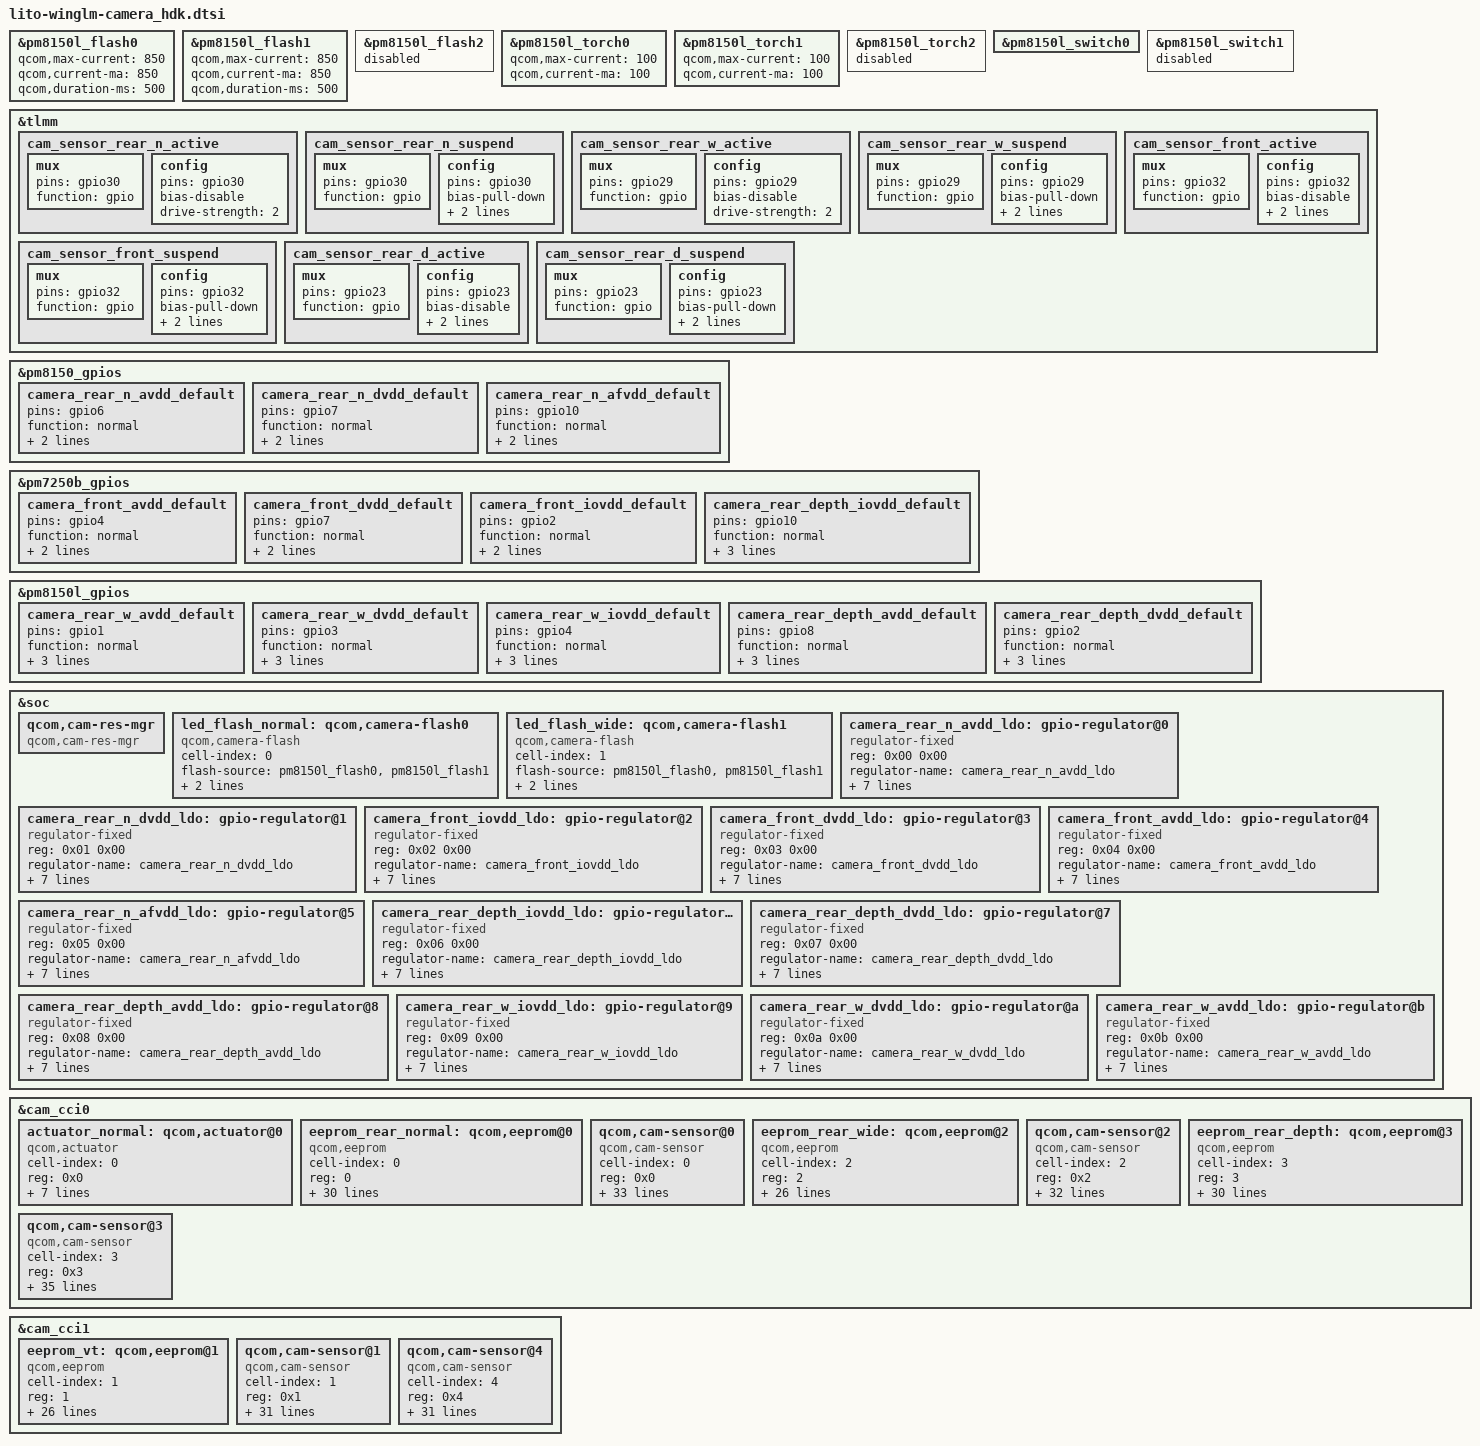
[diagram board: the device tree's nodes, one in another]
#include <dt-bindings/clock/qcom,camcc-lito.h>

&pm8150l_flash0 {
	status = "ok";
	qcom,max-current = <850>;
	qcom,current-ma = <850>;
	qcom,duration-ms = <500>;
};

&pm8150l_flash1 {
	status = "ok";
	qcom,max-current = <850>;
	qcom,current-ma = <850>;
	qcom,duration-ms = <500>;
};

&pm8150l_flash2 {
	status = "disabled";
};

&pm8150l_torch0 {
	status = "ok";
	qcom,max-current = <100>;
	qcom,current-ma = <100>;
};

&pm8150l_torch1 {
	status = "ok";
	qcom,max-current = <100>;
	qcom,current-ma = <100>;
};

&pm8150l_torch2 {
	status = "disabled";
};

&pm8150l_switch0 {
	status = "ok";
};

&pm8150l_switch1 {
	status = "disbled";
};

&tlmm{
	cam_sensor_rear_n_active: cam_sensor_rear_n_active {
		mux {
			pins = "gpio30";
			function = "gpio";
		};

		config {
			pins = "gpio30";
			bias-disable;
			drive-strength = <2>;
		};
	};

	cam_sensor_rear_n_suspend: cam_sensor_rear_n_suspend {
		mux {
			pins = "gpio30";
			function = "gpio";
		};

		config {
			pins = "gpio30";
			bias-pull-down;
			drive-strength = <2>;
			output-low;
		};
	};

	cam_sensor_rear_w_active: cam_sensor_rear_w_active {
		mux {
			pins = "gpio29";
			function = "gpio";
		};

		config {
			pins = "gpio29";
			bias-disable;
			drive-strength = <2>;
		};
	};

	cam_sensor_rear_w_suspend: cam_sensor_rear_w_suspend {
		mux {
			pins = "gpio29";
			function = "gpio";
		};

		config {
			pins = "gpio29";
			bias-pull-down;
			drive-strength = <2>;
			output-low;
		};
	};

	cam_sensor_front_active: cam_sensor_front_active {
		mux {
			pins = "gpio32";
			function = "gpio";
		};

		config {
			pins = "gpio32";
			bias-disable;
			drive-strength = <2>;
			output-low;
		};
	};

	cam_sensor_front_suspend: cam_sensor_front_suspend {
		mux {
			pins = "gpio32";
			function = "gpio";
		};

		config {
			pins = "gpio32";
			bias-pull-down;
			drive-strength = <2>;
			output-low;
		};
	};

	cam_sensor_rear_d_active: cam_sensor_rear_d_active {
		mux {
			pins = "gpio23";
			function = "gpio";
		};

		config {
			pins = "gpio23";
			bias-disable;
			drive-strength = <2>;
			output-low;
		};
	};
	
	cam_sensor_rear_d_suspend: cam_sensor_rear_d_suspend {
		mux {
			pins = "gpio23";
			function = "gpio";
		};

		config {
			pins = "gpio23";
			bias-pull-down;
			drive-strength = <2>;
			output-low;
		};
	};
};

&pm8150_gpios {
	camera_rear_n_avdd_default: camera_rear_n_avdd_default {
		pins = "gpio6";
		function = "normal";
		power-source = <0>;
		output-high;
	};

	camera_rear_n_dvdd_default: camera_rear_n_dvdd_default {
		pins = "gpio7";
		function = "normal";
		power-source = <0>;
		output-high;
	};

	camera_rear_n_afvdd_default: camera_rear_n_afvdd_default {
		pins = "gpio10";
		function = "normal";
		power-source = <0>;
		output-high;
	};
};

&pm7250b_gpios {
	camera_front_avdd_default: camera_front_avdd_default {
		pins = "gpio4";
		function = "normal";
		power-source = <0>;
		output-high;
	};

	camera_front_dvdd_default: camera_front_dvdd_default {
		pins = "gpio7";
		function = "normal";
		power-source = <0>;
		output-high;
	};

	camera_front_iovdd_default: camera_front_iovdd_default {
		pins = "gpio2";
		function = "normal";
		power-source = <0>;
		output-high;
	};

	camera_rear_depth_iovdd_default: camera_rear_depth_iovdd_default {
		pins = "gpio10";
		function = "normal";
		power-source = <0>;
		input-disable;
		output-high;
	};
};

&pm8150l_gpios {
	camera_rear_w_avdd_default: camera_rear_w_avdd_default {
		pins = "gpio1";
		function = "normal";
		power-source = <0>;
		input-disable;
		output-high;
	};

	camera_rear_w_dvdd_default: camera_rear_w_dvdd_default {
		pins = "gpio3";
		function = "normal";
		power-source = <0>;
		input-disable;
		output-high;
	};

	camera_rear_w_iovdd_default: camera_rear_w_iovdd_default {
		pins = "gpio4";
		function = "normal";
		power-source = <0>;
		input-disable;
		output-high;
	};

	camera_rear_depth_avdd_default: camera_rear_depth_avdd_default {
		pins = "gpio8";
		function = "normal";
		power-source = <0>;
		input-disable;
		output-high;
	};
	
	camera_rear_depth_dvdd_default: camera_rear_depth_dvdd_default {
		pins = "gpio2";
		function = "normal";
		power-source = <0>;
		input-disable;
		output-high;
	};
};

&soc {
	qcom,cam-res-mgr {
		compatible = "qcom,cam-res-mgr";
		status = "ok";
	};

	led_flash_normal: qcom,camera-flash0 {
		cell-index = <0>;
		compatible = "qcom,camera-flash";
		flash-source = <&pm8150l_flash0 &pm8150l_flash1>;
		torch-source = <&pm8150l_torch0 &pm8150l_torch1>;
		switch-source = <&pm8150l_switch2>;
		status = "ok";
	};

	led_flash_wide: qcom,camera-flash1 {
		cell-index = <1>;
		compatible = "qcom,camera-flash";
		flash-source = <&pm8150l_flash0 &pm8150l_flash1>;
		torch-source = <&pm8150l_torch0 &pm8150l_torch1>;
		switch-source = <&pm8150l_switch2>;
		status = "ok";
	};

	camera_rear_n_avdd_ldo: gpio-regulator@0 {
		compatible = "regulator-fixed";
		reg = <0x00 0x00>;
		regulator-name = "camera_rear_n_avdd_ldo";
		regulator-min-microvolt = <2800000>;
		regulator-max-microvolt = <2800000>;
		regulator-enable-ramp-delay = <135>;
		enable-active-high;
		gpio = <&pm8150_gpios 6 0>;
		pinctrl-names = "default";
		pinctrl-0 = <&camera_rear_n_avdd_default>;
		vin-supply = <&BOB>;
	};

	camera_rear_n_dvdd_ldo: gpio-regulator@1 {
		compatible = "regulator-fixed";
		reg = <0x01 0x00>;
		regulator-name = "camera_rear_n_dvdd_ldo";
		regulator-min-microvolt = <1050000>;
		regulator-max-microvolt = <1050000>;
		regulator-enable-ramp-delay = <135>;
		enable-active-high;
		gpio = <&pm8150_gpios 7 0>;
		pinctrl-names = "default";
		pinctrl-0 = <&camera_rear_n_dvdd_default>;
		vin-supply = <&S5A>;
	};

	camera_front_iovdd_ldo: gpio-regulator@2 {
		compatible = "regulator-fixed";
		reg = <0x02 0x00>;
		regulator-name = "camera_front_iovdd_ldo";
		regulator-min-microvolt = <1800000>;
		regulator-max-microvolt = <1800000>;
		regulator-enable-ramp-delay = <135>;
		enable-active-high;
		gpio = <&pm7250b_gpios 2 0>;
		pinctrl-names = "default";
		pinctrl-0 = <&camera_front_iovdd_default>;
		vin-supply = <&BOB>;
	};

	camera_front_dvdd_ldo: gpio-regulator@3 {
		compatible = "regulator-fixed";
		reg = <0x03 0x00>;
		regulator-name = "camera_front_dvdd_ldo";
		regulator-min-microvolt = <1050000>;
		regulator-max-microvolt = <1050000>;
		regulator-enable-ramp-delay = <135>;
		enable-active-high;
		gpio = <&pm7250b_gpios 7 0>;
		pinctrl-names = "default";
		pinctrl-0 = <&camera_front_dvdd_default>;
		vin-supply = <&S5A>;
	};

	camera_front_avdd_ldo: gpio-regulator@4 {
		compatible = "regulator-fixed";
		reg = <0x04 0x00>;
		regulator-name = "camera_front_avdd_ldo";
		regulator-min-microvolt = <2800000>;
		regulator-max-microvolt = <2800000>;
		regulator-enable-ramp-delay = <135>;
		enable-active-high;
		gpio = <&pm7250b_gpios 4 0>;
		pinctrl-names = "default";
		pinctrl-0 = <&camera_front_avdd_default>;
		vin-supply = <&BOB>;
	};

	camera_rear_n_afvdd_ldo: gpio-regulator@5 {
		compatible = "regulator-fixed";
		reg = <0x05 0x00>;
		regulator-name = "camera_rear_n_afvdd_ldo";
		regulator-min-microvolt = <2800000>;
		regulator-max-microvolt = <2800000>;
		regulator-enable-ramp-delay = <135>;
		enable-active-high;
		gpio = <&pm8150_gpios 10 0>;
		pinctrl-names = "default";
		pinctrl-0 = <&camera_rear_n_afvdd_default>;
		vin-supply = <&BOB>;
	};

	camera_rear_depth_iovdd_ldo: gpio-regulator@6 {
		compatible = "regulator-fixed";
		reg = <0x06 0x00>;
		regulator-name = "camera_rear_depth_iovdd_ldo";
		regulator-min-microvolt = <1800000>;
		regulator-max-microvolt = <1800000>;
		regulator-enable-ramp-delay = <135>;
		enable-active-high;
		gpio = <&pm7250b_gpios 10 0>;
		pinctrl-names = "default";
		pinctrl-0 = <&camera_rear_depth_iovdd_default>;
		vin-supply = <&BOB>;
	};
	
	camera_rear_depth_dvdd_ldo: gpio-regulator@7 {
		compatible = "regulator-fixed";
		reg = <0x07 0x00>;
		regulator-name = "camera_rear_depth_dvdd_ldo";
		regulator-min-microvolt = <1200000>;
		regulator-max-microvolt = <1200000>;
		regulator-enable-ramp-delay = <135>;
		enable-active-high;
		gpio = <&pm8150l_gpios 2 0>;
		pinctrl-names = "default";
		pinctrl-0 = <&camera_rear_depth_dvdd_default>;
		vin-supply = <&S5A>;
	};

	camera_rear_depth_avdd_ldo: gpio-regulator@8 {
		compatible = "regulator-fixed";
		reg = <0x08 0x00>;
		regulator-name = "camera_rear_depth_avdd_ldo";
		regulator-min-microvolt = <2800000>;
		regulator-max-microvolt = <2800000>;
		regulator-enable-ramp-delay = <135>;
		enable-active-high;
		gpio = <&pm8150l_gpios 8 0>;
		pinctrl-names = "default";
		pinctrl-0 = <&camera_rear_depth_avdd_default>;
		vin-supply = <&BOB>;
	};

	camera_rear_w_iovdd_ldo: gpio-regulator@9 {
		compatible = "regulator-fixed";
		reg = <0x09 0x00>;
		regulator-name = "camera_rear_w_iovdd_ldo";
		regulator-min-microvolt = <1800000>;
		regulator-max-microvolt = <1800000>;
		regulator-enable-ramp-delay = <135>;
		enable-active-high;
		gpio = <&pm8150l_gpios 4 0>;
		pinctrl-names = "default";
		pinctrl-0 = <&camera_rear_w_iovdd_default>;
		vin-supply = <&BOB>;
	};

	camera_rear_w_dvdd_ldo: gpio-regulator@a {
		compatible = "regulator-fixed";
		reg = <0x0a 0x00>;
		regulator-name = "camera_rear_w_dvdd_ldo";
		regulator-min-microvolt = <1200000>;
		regulator-max-microvolt = <1200000>;
		regulator-enable-ramp-delay = <135>;
		enable-active-high;
		gpio = <&pm8150l_gpios 3 0>;
		pinctrl-names = "default";
		pinctrl-0 = <&camera_rear_w_dvdd_default>;
		vin-supply = <&S5A>;
	};

	camera_rear_w_avdd_ldo: gpio-regulator@b {
		compatible = "regulator-fixed";
		reg = <0x0b 0x00>;
		regulator-name = "camera_rear_w_avdd_ldo";
		regulator-min-microvolt = <2800000>;
		regulator-max-microvolt = <2800000>;
		regulator-enable-ramp-delay = <135>;
		enable-active-high;
		gpio = <&pm8150l_gpios 1 0>;
		pinctrl-names = "default";
		pinctrl-0 = <&camera_rear_w_avdd_default>;
		vin-supply = <&BOB>;
	};
};

&cam_cci0 {
	actuator_normal: qcom,actuator@0 {
		cell-index = <0>;
		reg = <0x0>;
		compatible = "qcom,actuator";
		cci-master = <0>;
		cam_vaf-supply = <&camera_rear_n_afvdd_ldo>;
		regulator-names = "cam_vaf";
		rgltr-cntrl-support;
		rgltr-min-voltage = <2800000>;
		rgltr-max-voltage = <2800000>;
		rgltr-load-current = <100000>;
		status = "ok";
	};

	eeprom_rear_normal: qcom,eeprom@0 {
		cell-index = <0>;
		reg = <0>;
		compatible = "qcom,eeprom";
		cam_vio-supply = <&L17A>;
		cam_vana-supply = <&camera_rear_n_avdd_ldo>;
		cam_vdig-supply = <&camera_rear_n_dvdd_ldo>;
		cam_clk-supply = <&titan_top_gdsc>;
		cam_vaf-supply = <&camera_rear_n_afvdd_ldo>;
		regulator-names = "cam_vio", "cam_vana", "cam_vdig",
			"cam_clk", "cam_vaf";
		rgltr-cntrl-support;
		rgltr-min-voltage = <1800000 2800000 1050000 0 2800000>;
		rgltr-max-voltage = <1800000 2800000 1050000 0 2800000>;
		rgltr-load-current = <150000 150000 300000 0 100000>;
		gpio-no-mux = <0>;
		pinctrl-names = "cam_default", "cam_suspend";
		pinctrl-0 = <&cam_sensor_mclk0_active
				 &cam_sensor_rear_n_active>;
		pinctrl-1 = <&cam_sensor_mclk0_suspend
				 &cam_sensor_rear_n_suspend>;
		gpios = <&tlmm 13 0>,
			<&tlmm 30 0>;
		gpio-reset = <1>;
		gpio-req-tbl-num = <0 1>;
		gpio-req-tbl-flags = <1 0>;
		gpio-req-tbl-label = "CAMIF_MCLK0",
					"CAM_RESET0";
		sensor-position = <0>;
		sensor-mode = <0>;
		cci-master = <0>;
		status = "ok";
		clocks = <&camcc CAM_CC_MCLK0_CLK>;
		clock-names = "cam_clk";
		clock-cntl-level = "turbo";
		clock-rates = <19200000>;
	};

	qcom,cam-sensor@0 {
		cell-index = <0>;
		compatible = "qcom,cam-sensor";
		reg = <0x0>;
		csiphy-sd-index = <0>;
		sensor-position-roll = <90>;
		sensor-position-pitch = <0>;
		sensor-position-yaw = <180>;
		eeprom-src = <&eeprom_rear_normal>;
		actuator-src = <&actuator_normal>;
		led-flash-src = <&led_flash_normal>;
		cam_vio-supply = <&L17A>;
		cam_vana-supply = <&camera_rear_n_avdd_ldo>;
		cam_vdig-supply = <&camera_rear_n_dvdd_ldo>;
		cam_clk-supply = <&titan_top_gdsc>;
		regulator-names = "cam_vio", "cam_vana", "cam_vdig", "cam_clk";
		rgltr-cntrl-support;
		rgltr-min-voltage = <1800000 2800000 1050000 0>;
		rgltr-max-voltage = <1800000 2800000 1050000 0>;
		rgltr-load-current = <150000 150000 300000 0>;
		gpio-no-mux = <0>;
		pinctrl-names = "cam_default", "cam_suspend";
		pinctrl-0 = <&cam_sensor_mclk0_active
				 &cam_sensor_rear_n_active>;
		pinctrl-1 = <&cam_sensor_mclk0_suspend
				 &cam_sensor_rear_n_suspend>;
		gpios = <&tlmm 13 0>,
			<&tlmm 30 0>;
		gpio-reset = <1>;
		gpio-req-tbl-num = <0 1>;
		gpio-req-tbl-flags = <1 0>;
		gpio-req-tbl-label = "CAMIF_MCLK0",
					"CAM_RESET0";
		sensor-mode = <0>;
		cci-device = <0>;
		cci-master = <0>;
		status = "ok";
		clocks = <&camcc CAM_CC_MCLK0_CLK>;
		clock-names = "cam_clk";
		clock-cntl-level = "turbo";
		clock-rates = <19200000>;
	};

	eeprom_rear_wide: qcom,eeprom@2 {
		cell-index = <2>;
		reg = <2>;
		compatible = "qcom,eeprom";
		cam_vio-supply = <&camera_rear_w_iovdd_ldo>;
		cam_vana-supply = <&camera_rear_w_avdd_ldo>;
		cam_vdig-supply = <&camera_rear_w_dvdd_ldo>;
		cam_clk-supply = <&titan_top_gdsc>;
		regulator-names = "cam_vio", "cam_vana", "cam_vdig", "cam_clk";
		rgltr-cntrl-support;
		rgltr-min-voltage = <1800000 2800000 1200000 0>;
		rgltr-max-voltage = <1800000 2800000 1200000 0>;
		rgltr-load-current = <150000 150000 300000 0>;
		gpio-no-mux = <0>;
		pinctrl-names = "cam_default", "cam_suspend";
		pinctrl-0 = <&cam_sensor_mclk1_active
				 &cam_sensor_rear_w_active>;
		pinctrl-1 = <&cam_sensor_mclk1_suspend
				 &cam_sensor_rear_w_suspend>;
		gpios = <&tlmm 14 0>,
			<&tlmm 29 0>;
		gpio-reset = <1>;
		gpio-req-tbl-num = <0 1>;
		gpio-req-tbl-flags = <1 0>;
		gpio-req-tbl-label = "CAMIF_MCLK1",
					"CAM_RESET1";
		sensor-position = <0>;
		sensor-mode = <0>;
		cci-master = <1>;
		status = "ok";
		clocks = <&camcc CAM_CC_MCLK1_CLK>;
		clock-names = "cam_clk";
		clock-cntl-level = "turbo";
		clock-rates = <19200000>;
	};

	qcom,cam-sensor@2 {
		cell-index = <2>;
		compatible = "qcom,cam-sensor";
		reg = <0x2>;
		csiphy-sd-index = <1>;
		sensor-position-roll = <90>;
		sensor-position-pitch = <0>;
		sensor-position-yaw = <180>;
		eeprom-src = <&eeprom_rear_wide>;
		led-flash-src = <&led_flash_wide>;
		cam_vio-supply = <&camera_rear_w_iovdd_ldo>;
		cam_vana-supply = <&camera_rear_w_avdd_ldo>;
		cam_vdig-supply = <&camera_rear_w_dvdd_ldo>;
		cam_clk-supply = <&titan_top_gdsc>;
		regulator-names = "cam_vio", "cam_vana", "cam_vdig", "cam_clk";
		rgltr-cntrl-support;
		rgltr-min-voltage = <1800000 2800000 1200000 0>;
		rgltr-max-voltage = <1800000 2800000 1200000 0>;
		rgltr-load-current = <150000 150000 300000 0>;
		gpio-no-mux = <0>;
		pinctrl-names = "cam_default", "cam_suspend";
		pinctrl-0 = <&cam_sensor_mclk1_active
				 &cam_sensor_rear_w_active>;
		pinctrl-1 = <&cam_sensor_mclk1_suspend
				 &cam_sensor_rear_w_suspend>;
		gpios = <&tlmm 14 0>,
			<&tlmm 29 0>;
		gpio-reset = <1>;
		gpio-req-tbl-num = <0 1>;
		gpio-req-tbl-flags = <1 0>;
		gpio-req-tbl-label = "CAMIF_MCLK1",
					"CAM_RESET1";
		sensor-mode = <0>;
		cci-device = <0>;
		cci-master = <1>;
		status = "ok";
		clocks = <&camcc CAM_CC_MCLK1_CLK>;
		clock-names = "cam_clk";
		clock-cntl-level = "turbo";
		clock-rates = <19200000>;
	};

	eeprom_rear_depth: qcom,eeprom@3 {
		cell-index = <3>;
		reg = <3>;
		compatible = "qcom,eeprom";
		cam_vio-supply = <&camera_rear_depth_iovdd_ldo>;
		cam_vana-supply = <&camera_rear_depth_avdd_ldo>;
		cam_vdig-supply = <&camera_rear_depth_dvdd_ldo>;
		cam_v_custom1-supply = <&camera_rear_w_iovdd_ldo>;
		cam_clk-supply = <&titan_top_gdsc>;
		regulator-names = "cam_vio", "cam_vana", "cam_vdig", "cam_clk", "cam_v_custom1";
		rgltr-cntrl-support;
		rgltr-min-voltage = <1800000 2800000 1200000 0 1800000>;
		rgltr-max-voltage = <1800000 2800000 1200000 0 1800000>;
		rgltr-load-current = <150000 150000 300000 0 150000>;
		gpio-no-mux = <0>;
		pinctrl-names = "cam_default", "cam_suspend";
		pinctrl-0 = <&cam_sensor_mclk3_active
				 &cam_sensor_rear_d_active>;
		pinctrl-1 = <&cam_sensor_mclk3_suspend
				 &cam_sensor_rear_d_suspend>;
		gpios = <&tlmm 16 0>,
			<&tlmm 23 0>;
		gpio-reset = <1>;
		gpio-req-tbl-num = <0 1>;
		gpio-req-tbl-flags = <1 0>;
		gpio-req-tbl-label = "DEPTH_MCLK",
					"DEPTH_RESET";
		sensor-position = <0>;
		sensor-mode = <0>;
		cci-master = <1>;
		status = "ok";
		clocks = <&camcc CAM_CC_MCLK3_CLK>;
		clock-names = "cam_clk";
		clock-cntl-level = "turbo";
		clock-rates = <19200000>;
	};

	qcom,cam-sensor@3 {
		cell-index = <3>;
		compatible = "qcom,cam-sensor";
		reg = <0x3>;
		csiphy-sd-index = <3>;
		sensor-position-roll = <90>;
		sensor-position-pitch = <0>;
		sensor-position-yaw = <180>;
		eeprom-src = <&eeprom_rear_depth>;
		cam_vio-supply = <&camera_rear_depth_iovdd_ldo>;
		cam_vana-supply = <&camera_rear_depth_avdd_ldo>;
		cam_vdig-supply = <&camera_rear_depth_dvdd_ldo>;
		cam_v_custom1-supply = <&camera_rear_w_iovdd_ldo>;
		cam_clk-supply = <&titan_top_gdsc>;
		regulator-names = "cam_vio", "cam_vana", "cam_vdig", "cam_clk", "cam_v_custom1";
		rgltr-cntrl-support;
		rgltr-min-voltage = <1800000 2800000 1200000 0 1800000>;
		rgltr-max-voltage = <1800000 2800000 1200000 0 1800000>;
		rgltr-load-current = <150000 150000 300000 0 150000>;
		gpio-no-mux = <0>;
		pinctrl-names = "cam_default", "cam_suspend";
		pinctrl-0 = <&cam_sensor_mclk3_active
				 &cam_sensor_rear_d_active>;
		pinctrl-1 = <&cam_sensor_mclk3_suspend
				 &cam_sensor_rear_d_suspend>;
		gpios = <&tlmm 16 0>,
			<&tlmm 23 0>;
		gpio-reset = <1>;
		gpio-req-tbl-num = <0 1>;
		gpio-req-tbl-flags = <1 0>;
		gpio-req-tbl-label = "DEPTH_MCLK",
					"DEPTH_RESET";
		sensor-mode = <0>;
		cci-device = <0>;
		cci-master = <1>;
		status = "ok";
		clocks = <&camcc CAM_CC_MCLK3_CLK>;
		clock-names = "cam_clk";
		clock-cntl-level = "turbo";
		clock-rates = <19200000>;
	};
};

&cam_cci1 {
	eeprom_vt: qcom,eeprom@1 {
		cell-index = <1>;
		reg = <1>;
		compatible = "qcom,eeprom";
		cam_vio-supply = <&camera_front_iovdd_ldo>;
		cam_vana-supply = <&camera_front_avdd_ldo>;
		cam_vdig-supply = <&camera_front_dvdd_ldo>;
		cam_clk-supply = <&titan_top_gdsc>;
		regulator-names = "cam_vio", "cam_vana", "cam_vdig", "cam_clk";
		rgltr-cntrl-support;
		rgltr-min-voltage = <1800000 2800000 1050000 0>;
		rgltr-max-voltage = <1800000 2800000 1050000 0>;
		rgltr-load-current = <150000 150000 150000 0>;
		gpio-no-mux = <0>;
		pinctrl-names = "cam_default", "cam_suspend";
		pinctrl-0 = <&cam_sensor_mclk2_active
				 &cam_sensor_front_active>;
		pinctrl-1 = <&cam_sensor_mclk2_suspend
				 &cam_sensor_front_suspend>;
		gpios = <&tlmm 15 0>,
			<&tlmm 32 0>;
		gpio-reset = <1>;
		gpio-req-tbl-num = <0 1>;
		gpio-req-tbl-flags = <1 0>;
		gpio-req-tbl-label = "VT_MCLK",
					"VT_RESET";
		sensor-position = <0>;
		sensor-mode = <0>;
		cci-master = <0>;
		status = "ok";
		clocks = <&camcc CAM_CC_MCLK2_CLK>;
		clock-names = "cam_clk";
		clock-cntl-level = "turbo";
		clock-rates = <19200000>;
	};

	qcom,cam-sensor@1 {
		cell-index = <1>;
		compatible = "qcom,cam-sensor";
		reg = <0x1>;
		csiphy-sd-index = <2>;
		sensor-position-roll = <270>;
		sensor-position-pitch = <0>;
		sensor-position-yaw = <0>;
		eeprom-src = <&eeprom_vt>;
		cam_vio-supply = <&camera_front_iovdd_ldo>;
		cam_vana-supply = <&camera_front_avdd_ldo>;
		cam_vdig-supply = <&camera_front_dvdd_ldo>;
		cam_clk-supply = <&titan_top_gdsc>;
		regulator-names = "cam_vio", "cam_vana", "cam_vdig", "cam_clk";
		rgltr-cntrl-support;
		rgltr-min-voltage = <1800000 2800000 1050000 0>;
		rgltr-max-voltage = <1800000 2800000 1050000 0>;
		rgltr-load-current = <150000 150000 150000 0>;
		gpio-no-mux = <0>;
		pinctrl-names = "cam_default", "cam_suspend";
		pinctrl-0 = <&cam_sensor_mclk2_active
				 &cam_sensor_front_active>;
		pinctrl-1 = <&cam_sensor_mclk2_suspend
				 &cam_sensor_front_suspend>;
		gpios = <&tlmm 15 0>,
			<&tlmm 32 0>;
		gpio-reset = <1>;
		gpio-req-tbl-num = <0 1>;
		gpio-req-tbl-flags = <1 0>;
		gpio-req-tbl-label = "VT_MCLK",
					"VT_RESET";
		sensor-mode = <0>;
		cci-device = <1>;
		cci-master = <0>;
		status = "ok";
		clocks = <&camcc CAM_CC_MCLK2_CLK>;
		clock-names = "cam_clk";
		clock-cntl-level = "turbo";
		clock-rates = <19200000>;
	};

	qcom,cam-sensor@4 {
		cell-index = <4>;
		compatible = "qcom,cam-sensor";
		reg = <0x4>;
		csiphy-sd-index = <2>;
		sensor-position-roll = <90>;
		sensor-position-pitch = <0>;
		sensor-position-yaw = <0>;
		eeprom-src = <&eeprom_vt>;
		cam_vio-supply = <&camera_front_iovdd_ldo>;
		cam_vana-supply = <&camera_front_avdd_ldo>;
		cam_vdig-supply = <&camera_front_dvdd_ldo>;
		cam_clk-supply = <&titan_top_gdsc>;
		regulator-names = "cam_vio", "cam_vana", "cam_vdig", "cam_clk";
		rgltr-cntrl-support;
		rgltr-min-voltage = <1800000 2800000 1050000 0>;
		rgltr-max-voltage = <1800000 2800000 1050000 0>;
		rgltr-load-current = <150000 150000 150000 0>;
		gpio-no-mux = <0>;
		pinctrl-names = "cam_default", "cam_suspend";
		pinctrl-0 = <&cam_sensor_mclk2_active
				 &cam_sensor_front_active>;
		pinctrl-1 = <&cam_sensor_mclk2_suspend
				 &cam_sensor_front_suspend>;
		gpios = <&tlmm 15 0>,
			<&tlmm 32 0>;
		gpio-reset = <1>;
		gpio-req-tbl-num = <0 1>;
		gpio-req-tbl-flags = <1 0>;
		gpio-req-tbl-label = "VT_MCLK",
					"VT_RESET";
		sensor-mode = <0>;
		cci-device = <1>;
		cci-master = <0>;
		status = "ok";
		clocks = <&camcc CAM_CC_MCLK2_CLK>;
		clock-names = "cam_clk";
		clock-cntl-level = "turbo";
		clock-rates = <19200000>;
	};
};
